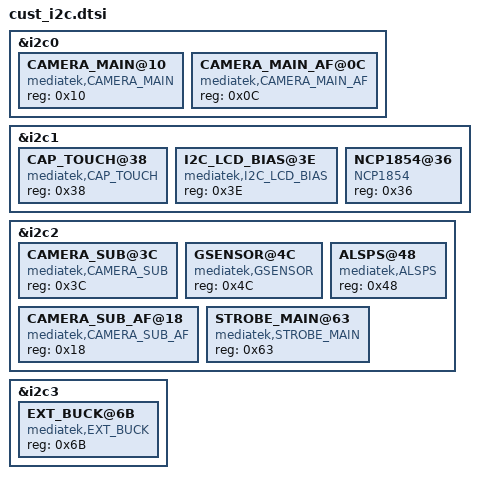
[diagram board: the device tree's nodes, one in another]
/*
 * Generated by MTK SP DrvGen Version 03.13.6 for MT6735M. Copyright MediaTek Inc. (C) 2013.
 * Mon May 29 15:48:37 2017
 * Do Not Modify the File.
 */

/*************************
 * I2C DTSI File
*************************/

&i2c0 {
	CAMERA_MAIN@10 {
		compatible = "mediatek,CAMERA_MAIN";
		reg = <0x10>;
	};

	CAMERA_MAIN_AF@0C {
		compatible = "mediatek,CAMERA_MAIN_AF";
		reg = <0x0C>;
	};

};

&i2c1 {
	CAP_TOUCH@38 {
		compatible = "mediatek,CAP_TOUCH";
		reg = <0x38>;
	};

	I2C_LCD_BIAS@3E {
		compatible = "mediatek,I2C_LCD_BIAS";
		reg = <0x3E>;
	};

	NCP1854@36 {
		compatible = "NCP1854";
		reg = <0x36>;
	};

};

&i2c2 {
	CAMERA_SUB@3C {
		compatible = "mediatek,CAMERA_SUB";
		reg = <0x3C>;
	};

	GSENSOR@4C {
		compatible = "mediatek,GSENSOR";
		reg = <0x4C>;
	};

	ALSPS@48 {
		compatible = "mediatek,ALSPS";
		reg = <0x48>;
	};

	CAMERA_SUB_AF@18 {
		compatible = "mediatek,CAMERA_SUB_AF";
		reg = <0x18>;
	};

	STROBE_MAIN@63 {
		compatible = "mediatek,STROBE_MAIN";
		reg = <0x63>;
	};

};

&i2c3 {
	EXT_BUCK@6B {
		compatible = "mediatek,EXT_BUCK";
		reg = <0x6B>;
	};

};

